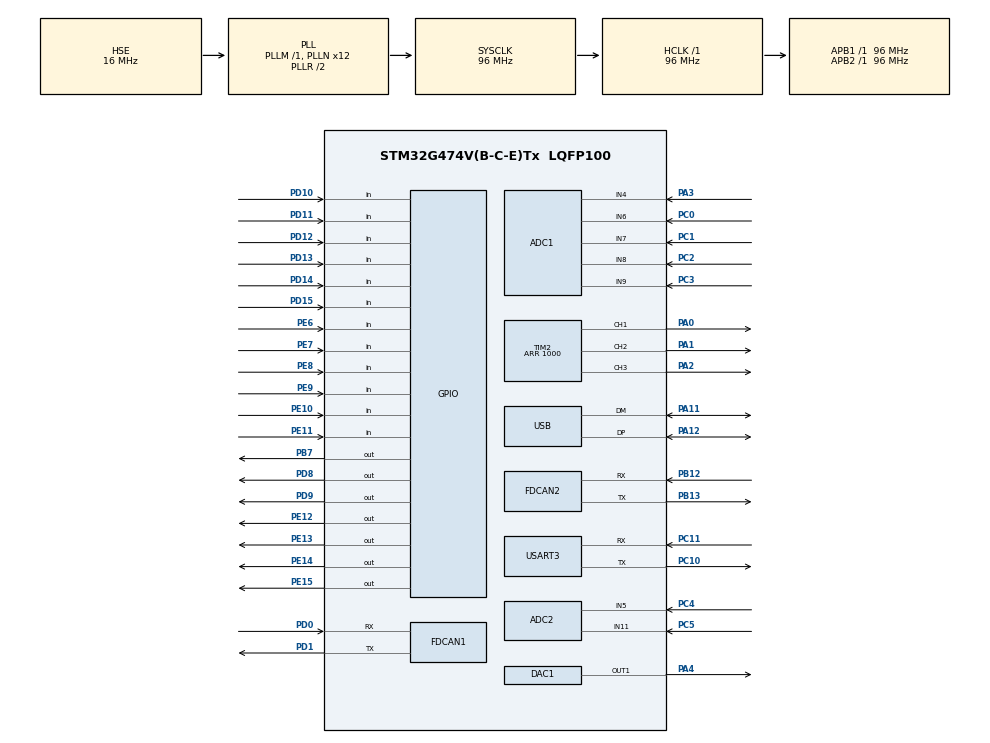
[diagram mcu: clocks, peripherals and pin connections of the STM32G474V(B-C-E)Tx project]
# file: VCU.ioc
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ADC1.Channel-1\#ChannelRegularConversion=ADC_CHANNEL_6
ADC1.Channel-2\#ChannelRegularConversion=ADC_CHANNEL_7
ADC1.Channel-3\#ChannelRegularConversion=ADC_CHANNEL_8
ADC1.Channel-4\#ChannelRegularConversion=ADC_CHANNEL_9
ADC1.EnableAnalogWatchDog3=true
ADC1.MonitoredBy-2\#ChannelRegularConversion=__NULL
ADC1.MonitoredBy-3\#ChannelRegularConversion=__NULL
ADC1.MonitoredBy-4\#ChannelRegularConversion=__NULL
ADC1.NbrOfConversion=4
ADC1.NbrOfConversionFlag=1
ADC1.OffsetNumber-1\#ChannelRegularConversion=ADC_OFFSET_NONE
ADC1.OffsetNumber-2\#ChannelRegularConversion=ADC_OFFSET_NONE
ADC1.OffsetNumber-3\#ChannelRegularConversion=ADC_OFFSET_NONE
ADC1.OffsetNumber-4\#ChannelRegularConversion=ADC_OFFSET_NONE
ADC1.Rank-1\#ChannelRegularConversion=1
ADC1.Rank-2\#ChannelRegularConversion=2
ADC1.Rank-3\#ChannelRegularConversion=3
ADC1.Rank-4\#ChannelRegularConversion=4
ADC1.SamplingTime-1\#ChannelRegularConversion=ADC_SAMPLETIME_24CYCLES_5
ADC1.SamplingTime-2\#ChannelRegularConversion=ADC_SAMPLETIME_24CYCLES_5
ADC1.SamplingTime-3\#ChannelRegularConversion=ADC_SAMPLETIME_24CYCLES_5
ADC1.SamplingTime-4\#ChannelRegularConversion=ADC_SAMPLETIME_24CYCLES_5
ADC1.master=1
ADC2.Channel-0\#ChannelRegularConversion=ADC_CHANNEL_5
ADC2.NbrOfConversionFlag=1
ADC2.OffsetNumber-0\#ChannelRegularConversion=ADC_OFFSET_NONE
ADC2.Rank-0\#ChannelRegularConversion=1
ADC2.SamplingTime-0\#ChannelRegularConversion=ADC_SAMPLETIME_24CYCLES_5
Dma.ADC1.0.Direction=DMA_PERIPH_TO_MEMORY
Dma.ADC1.0.EventEnable=DISABLE
Dma.ADC1.0.Instance=DMA1_Channel1
Dma.ADC1.0.MemDataAlignment=DMA_MDATAALIGN_HALFWORD
Dma.ADC1.0.MemInc=DMA_MINC_ENABLE
Dma.ADC1.0.Mode=DMA_CIRCULAR
Dma.ADC1.0.PeriphDataAlignment=DMA_PDATAALIGN_HALFWORD
Dma.ADC1.0.PeriphInc=DMA_PINC_DISABLE
Dma.ADC1.0.Polarity=HAL_DMAMUX_REQ_GEN_RISING
Dma.ADC1.0.Priority=DMA_PRIORITY_MEDIUM
Dma.ADC1.0.RequestNumber=1
Dma.ADC1.0.SignalID=NONE
Dma.ADC1.0.SyncEnable=DISABLE
Dma.ADC1.0.SyncPolarity=HAL_DMAMUX_SYNC_NO_EVENT
Dma.ADC1.0.SyncRequestNumber=1
Dma.ADC1.0.SyncSignalID=NONE
Dma.Request0=ADC1
FDCAN1.AutoRetransmission=ENABLE
FDCAN1.CalculateBaudRateNominal=1000000
FDCAN1.CalculateTimeBitNominal=1000
FDCAN1.CalculateTimeQuantumNominal=125.0
FDCAN1.Mode=FDCAN_MODE_NORMAL
FDCAN1.NominalPrescaler=12
FDCAN1.NominalTimeSeg1=5
FDCAN1.NominalTimeSeg2=2
FDCAN1.TransmitPause=DISABLE
FDCAN1.TxFifoQueueMode=FDCAN_TX_FIFO_OPERATION
FDCAN2.CalculateBaudRateNominal=1000000
FDCAN2.CalculateTimeBitNominal=1000
FDCAN2.AutoRetransmission=ENABLE
FDCAN2.CalculateTimeQuantumNominal=125.0
FDCAN2.NominalPrescaler=12
FDCAN2.NominalTimeSeg1=5
FDCAN2.NominalTimeSeg2=2
FREERTOS.Tasks01=defaultTask,24,128,StartDefaultTask,Default,NULL,Dynamic,NULL,NULL
FREERTOS.configTOTAL_HEAP_SIZE=16384
Mcu.Family=STM32G4
Mcu.Name=STM32G474V(B-C-E)Tx
Mcu.Package=LQFP100
NVIC.DMA1_Channel1_IRQn=true\:10\:0\:true\:false\:true\:true\:false\:true\:true
NVIC.FDCAN1_IT0_IRQn=true\:5\:0\:false\:false\:true\:true\:true\:true\:true
NVIC.FDCAN1_IT1_IRQn=true\:5\:0\:false\:false\:true\:true\:true\:true\:true
NVIC.FDCAN2_IT0_IRQn=true\:5\:0\:false\:false\:true\:true\:true\:true\:true
NVIC.FDCAN2_IT1_IRQn=true\:5\:0\:false\:false\:true\:true\:true\:true\:true
NVIC.PriorityGroup=NVIC_PRIORITYGROUP_4
NVIC.TIM20_UP_IRQn=true\:15\:0\:false\:false\:true\:false\:false\:true\:true
NVIC.TimeBase=TIM20_UP_IRQn
NVIC.TimeBaseIP=TIM20
NVIC.USB_LP_IRQn=true\:5\:0\:false\:false\:true\:true\:false\:true\:true
PA0.Signal=S_TIM2_CH1
PA1.Signal=S_TIM2_CH2
PA11.Mode=Device
PA11.Signal=USB_DM
PA12.Mode=Device
PA12.Signal=USB_DP
PA13.Mode=Trace_Asynchronous_SW
PA13.Signal=SYS_JTMS-SWDIO
PA14.Mode=Trace_Asynchronous_SW
PA14.Signal=SYS_JTCK-SWCLK
PA2.Signal=S_TIM2_CH3
PA3.Mode=IN4-Single-Ended
PA3.Signal=ADC1_IN4
PA4.Signal=COMP_DAC11_group
PB12.Mode=FDCAN_Activate
PB12.Signal=FDCAN2_RX
PB13.Mode=FDCAN_Activate
PB13.Signal=FDCAN2_TX
PB3.Mode=Trace_Asynchronous_SW
PB3.Signal=SYS_JTDO-SWO
PB7.Signal=GPIO_Output
PC0.Mode=IN6-Single-Ended
PC0.Signal=ADC1_IN6
PC1.Mode=IN7-Single-Ended
PC1.Signal=ADC1_IN7
PC10.Mode=Asynchronous
PC10.Signal=USART3_TX
PC11.Mode=Asynchronous
PC11.Signal=USART3_RX
PC2.Mode=IN8-Single-Ended
PC2.Signal=ADC1_IN8
PC3.Mode=IN9-Single-Ended
PC3.Signal=ADC1_IN9
PC4.Mode=IN5-Single-Ended
PC4.Signal=ADC2_IN5
PC5.Mode=IN11-Single-Ended
PC5.Signal=ADC2_IN11
PD0.Mode=FDCAN_Activate
PD0.Signal=FDCAN1_RX
PD1.Mode=FDCAN_Activate
PD1.Signal=FDCAN1_TX
PD10.Signal=GPIO_Input
PD11.Signal=GPIO_Input
PD12.Signal=GPIO_Input
PD13.Signal=GPIO_Input
PD14.Signal=GPIO_Input
PD15.Signal=GPIO_Input
PD8.Signal=GPIO_Output
PD9.Signal=GPIO_Output
PE10.Signal=GPIO_Input
PE11.Signal=GPIO_Input
PE12.Signal=GPIO_Output
PE13.Signal=GPIO_Output
PE14.Signal=GPIO_Output
PE15.Signal=GPIO_Output
PE6.Signal=GPIO_Input
PE7.Signal=GPIO_Input
PE8.Signal=GPIO_Input
PE9.Signal=GPIO_Input
PF0-OSC_IN.Mode=HSE-External-Oscillator
PF0-OSC_IN.Signal=RCC_OSC_IN
PF1-OSC_OUT.Mode=HSE-External-Oscillator
PF1-OSC_OUT.Signal=RCC_OSC_OUT
ProjectManager.HeapSize=0x200
ProjectManager.StackSize=0x400
ProjectManager.TargetToolchain=Makefile
RCC.ADC12Freq_Value=96000000
RCC.ADC345Freq_Value=96000000
RCC.AHBFreq_Value=96000000
RCC.APB1Freq_Value=96000000
RCC.APB1TimFreq_Value=96000000
RCC.APB2Freq_Value=96000000
RCC.APB2TimFreq_Value=96000000
RCC.CortexFreq_Value=96000000
RCC.EXTERNAL_CLOCK_VALUE=12288000
RCC.HCLKFreq_Value=96000000
RCC.HSE_VALUE=16000000
RCC.HSI48_VALUE=48000000
RCC.HSI_VALUE=16000000
RCC.LSE_VALUE=32768
RCC.PLLN=12
RCC.PLLQ=RCC_PLLQ_DIV4
RCC.PLLSourceVirtual=RCC_PLLSOURCE_HSE
RCC.SYSCLKFreq_VALUE=96000000
RCC.SYSCLKSource=RCC_SYSCLKSOURCE_PLLCLK
RCC.USBFreq_Value=48000000
RCC.VCOOutputFreq_Value=192000000
SH.COMP_DAC11_group.0=DAC1_OUT1,DAC_OUT1
SH.S_TIM2_CH1.0=TIM2_CH1,PWM Generation1 CH1
SH.S_TIM2_CH2.0=TIM2_CH2,PWM Generation2 CH2
SH.S_TIM2_CH3.0=TIM2_CH3,PWM Generation3 CH3
TIM2.Channel-PWM\ Generation1\ CH1=TIM_CHANNEL_1
TIM2.Channel-PWM\ Generation2\ CH2=TIM_CHANNEL_2
TIM2.Channel-PWM\ Generation3\ CH3=TIM_CHANNEL_3
TIM2.Dithering=Disable
TIM2.OCFastMode_PWM-PWM\ Generation1\ CH1=TIM_OCFAST_ENABLE
TIM2.OCFastMode_PWM-PWM\ Generation2\ CH2=TIM_OCFAST_ENABLE
TIM2.OCFastMode_PWM-PWM\ Generation3\ CH3=TIM_OCFAST_ENABLE
TIM2.OCPolarity_1=TIM_OCPOLARITY_LOW
TIM2.OCPolarity_2=TIM_OCPOLARITY_LOW
TIM2.OCPolarity_3=TIM_OCPOLARITY_LOW
TIM2.PeriodNoDither=1000
USART3.FIFOMode=FIFOMODE_ENABLE
USART3.VirtualMode-Asynchronous=VM_ASYNC
USB_DEVICE.CLASS_NAME_FS=CDC
USB_DEVICE.MANUFACTURER_STRING=LHRe
USB_DEVICE.PRODUCT_STRING_CDC_FS=Vehicle Control Unit
USB_DEVICE.INTERFACE_STRING_CDC_FS=Vehicle Control Unit
USB_DEVICE.VirtualMode=Cdc
USB_DEVICE.VirtualModeFS=Cdc_FS
VP_FREERTOS_VS_CMSIS_V2.Mode=CMSIS_V2
VP_SYS_VS_DBSignals.Mode=DisableDeadBatterySignals
VP_SYS_VS_tim20.Mode=TIM20
VP_USB_DEVICE_VS_USB_DEVICE_CDC_FS.Mode=CDC_FS
board=custom

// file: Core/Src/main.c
/* USER CODE BEGIN Header */
/**
  ******************************************************************************
  * @file           : main.c
  * @brief          : Main program body
  ******************************************************************************
  * @attention
  *
  * Copyright (c) 2026 STMicroelectronics.
  * All rights reserved.
  *
  * This software is licensed under terms that can be found in the LICENSE file
  * in the root directory of this software component.
  * If no LICENSE file comes with this software, it is provided AS-IS.
  *
  ******************************************************************************
  */
/* USER CODE END Header */
#include "main.h"
#include "cmsis_os.h"
#include "adc.h"
#include "dac.h"
#include "dma.h"
#include "fdcan.h"
#include "tim.h"
#include "usart.h"
#include "usb_device.h"
#include "gpio.h"

void SystemClock_Config(void);
void MX_FREERTOS_Init(void);
/* USER CODE BEGIN PFP */
/* VCU.ioc currently has ProjectManager.NoMain=false, so CubeMX emits a main()
 * that collides with the hand-written one in Board/main.cpp and calls the
 * CMSIS-RTOS2 glue this build deliberately leaves out. Rename it out of the
 * way; nothing calls it and --gc-sections drops it. Delete this block once the
 * .ioc is back to NoMain=true (see boards/VCU/README.md). */
#define main vcu_cubemx_generated_main_unused
#define MX_FREERTOS_Init() ((void)0)
#define osKernelInitialize() ((void)0)
#define osKernelStart() ((void)0)
void vcu_board_force_safe_outputs(void); /* Board/board_safe_state.cpp */
/* USER CODE END PFP */

int main(void)
{

  /* MCU Configuration--------------------------------------------------------*/

  /* Reset of all peripherals, Initializes the Flash interface and the Systick. */
  HAL_Init();

  /* Configure the system clock */
  SystemClock_Config();

  /* Initialize all configured peripherals */
  MX_GPIO_Init();
  MX_DMA_Init();
  MX_ADC1_Init();
  MX_FDCAN1_Init();
  MX_FDCAN2_Init();
  MX_TIM2_Init();
  MX_ADC2_Init();
  MX_DAC1_Init();
  MX_USART3_UART_Init();

  /* Init scheduler */
  osKernelInitialize();

  /* Call init function for freertos objects (in cmsis_os2.c) */
  MX_FREERTOS_Init();

  /* Start scheduler */
  osKernelStart();

  /* We should never get here as control is now taken by the scheduler */

  /* Infinite loop */
  while (1)
  {

  }
}

void SystemClock_Config(void)
{
  RCC_OscInitTypeDef RCC_OscInitStruct = {0};
  RCC_ClkInitTypeDef RCC_ClkInitStruct = {0};

  /** Configure the main internal regulator output voltage
  */
  HAL_PWREx_ControlVoltageScaling(PWR_REGULATOR_VOLTAGE_SCALE1);

  /** Initializes the RCC Oscillators according to the specified parameters
  * in the RCC_OscInitTypeDef structure.
  */
  RCC_OscInitStruct.OscillatorType = RCC_OSCILLATORTYPE_HSE;
  RCC_OscInitStruct.HSEState = RCC_HSE_ON;
  RCC_OscInitStruct.PLL.PLLState = RCC_PLL_ON;
  RCC_OscInitStruct.PLL.PLLSource = RCC_PLLSOURCE_HSE;
  RCC_OscInitStruct.PLL.PLLM = RCC_PLLM_DIV1;
  RCC_OscInitStruct.PLL.PLLN = 12;
  RCC_OscInitStruct.PLL.PLLP = RCC_PLLP_DIV2;
  RCC_OscInitStruct.PLL.PLLQ = RCC_PLLQ_DIV4;
  RCC_OscInitStruct.PLL.PLLR = RCC_PLLR_DIV2;
  if (HAL_RCC_OscConfig(&RCC_OscInitStruct) != HAL_OK)
  {
    Error_Handler();
  }

  /** Initializes the CPU, AHB and APB buses clocks
  */
  RCC_ClkInitStruct.ClockType = RCC_CLOCKTYPE_HCLK|RCC_CLOCKTYPE_SYSCLK
                              |RCC_CLOCKTYPE_PCLK1|RCC_CLOCKTYPE_PCLK2;
  RCC_ClkInitStruct.SYSCLKSource = RCC_SYSCLKSOURCE_PLLCLK;
  RCC_ClkInitStruct.AHBCLKDivider = RCC_SYSCLK_DIV1;
  RCC_ClkInitStruct.APB1CLKDivider = RCC_HCLK_DIV1;
  RCC_ClkInitStruct.APB2CLKDivider = RCC_HCLK_DIV1;

  if (HAL_RCC_ClockConfig(&RCC_ClkInitStruct, FLASH_LATENCY_3) != HAL_OK)
  {
    Error_Handler();
  }
}

void HAL_TIM_PeriodElapsedCallback(TIM_HandleTypeDef *htim)
{
  if (htim->Instance == TIM20)
  {
    HAL_IncTick();
  }
}

void Error_Handler(void)
{
  /* USER CODE BEGIN Error_Handler_Debug */
  /* User can add his own implementation to report the HAL error return state */
  /* Outputs safe, then halt; the IWDG (if started) resets the MCU. */
  vcu_board_force_safe_outputs();
  __disable_irq();
  while (1)
  {
  }
  /* USER CODE END Error_Handler_Debug */
}

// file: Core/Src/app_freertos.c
/* USER CODE BEGIN Header */
/**
  ******************************************************************************
  * File Name          : app_freertos.c
  * Description        : Code for freertos applications
  ******************************************************************************
  * @attention
  *
  * Copyright (c) 2026 STMicroelectronics.
  * All rights reserved.
  *
  * This software is licensed under terms that can be found in the LICENSE file
  * in the root directory of this software component.
  * If no LICENSE file comes with this software, it is provided AS-IS.
  *
  ******************************************************************************
  */
/* USER CODE END Header */

#include "FreeRTOS.h"
#include "task.h"
#include "main.h"
#include "cmsis_os.h"

#include "usb_device.h"

/* Definitions for defaultTask */
osThreadId_t defaultTaskHandle;
const osThreadAttr_t defaultTask_attributes = {
  .name = "defaultTask",
  .priority = (osPriority_t) osPriorityNormal,
  .stack_size = 128 * 4
};

void StartDefaultTask(void *argument);

void MX_FREERTOS_Init(void); /* (MISRA C 2004 rule 8.1) */

void MX_FREERTOS_Init(void) {

  /* Create the thread(s) */
  /* creation of defaultTask */
  defaultTaskHandle = osThreadNew(StartDefaultTask, NULL, &defaultTask_attributes);

}

void StartDefaultTask(void *argument)
{
  /* init code for USB_Device */
  MX_USB_Device_Init();
  for(;;)
  {
    osDelay(1);
  }
}
